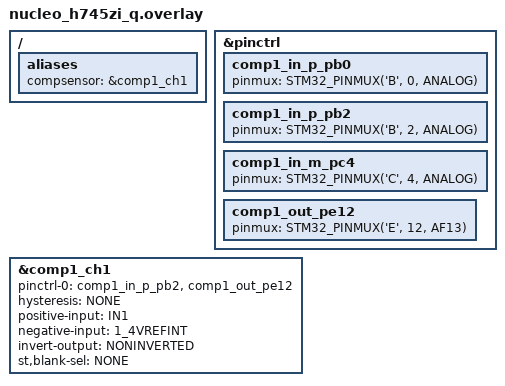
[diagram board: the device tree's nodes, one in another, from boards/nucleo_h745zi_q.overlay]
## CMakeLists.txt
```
# SPDX-License-Identifier: Apache-2.0
# Copyright (c) 2025 Alexander Kozhinov <ak.alexander.kozhinov@gmail.com>

cmake_minimum_required(VERSION 3.20.0)
find_package(Zephyr REQUIRED HINTS $ENV{ZEPHYR_BASE})
project(comparator)

target_sources(app PRIVATE src/main.c)
```

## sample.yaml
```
sample:
  name: Comparator API sample
tests:
  sample.drivers.comparator:
    tags:
      - comparator
    depends_on: comparator
    platform_allow:
      - nucleo_h745zi_q/stm32h745xx/m7
    harness: console
    timeout: 10
    harness_config:
      type: one_line
      regex:
        - "comparator@.* output: \\d+"
```

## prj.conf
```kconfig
CONFIG_GPIO=y
CONFIG_COMPARATOR=y

CONFIG_HW_STACK_PROTECTION=y

CONFIG_LOG=y
CONFIG_COMPARATOR_LOG_LEVEL_DBG=y
```

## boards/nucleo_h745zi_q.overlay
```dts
/*
 * SPDX-License-Identifier: Apache-2.0
 * Copyright (c) 2025 Alexander Kozhinov <ak.alexander.kozhinov@gmail.com>
 */

/ {
	aliases {
		compsensor = &comp1_ch1;
	};
};

&pinctrl {
	/omit-if-no-ref/ comp1_in_p_pb0: comp1_in_p_pb0 {
		pinmux = <STM32_PINMUX('B', 0, ANALOG)>;
	};

	/omit-if-no-ref/ comp1_in_p_pb2: comp1_in_p_pb2 {
		pinmux = <STM32_PINMUX('B', 2, ANALOG)>;
	};

	/omit-if-no-ref/ comp1_in_m_pc4: comp1_in_m_pc4 {
		pinmux = <STM32_PINMUX('C', 4, ANALOG)>;
	};

	/omit-if-no-ref/ comp1_out_pe12: comp1_out_pe12 {
		pinmux = <STM32_PINMUX('E', 12, AF13)>;
	};
};

/*
 * On nucleo-h745zi-q board the led0 is connected to PB0 (D33 on CN10).
 * led0 will be toggled every 3rd run of the main cycle as an GPIO thus
 * led0 will get on and off.
 * Thus the pin PB0 may be connected to PB2 (D27 on CN10) to trigger COMP1
 * state change.
 */
&comp1_ch1 {
	status = "okay";
	pinctrl-0 = <&comp1_in_p_pb2 &comp1_out_pe12>;
	pinctrl-names = "default";
	hysteresis = "NONE";
	positive-input = "IN1";
	negative-input = "1_4VREFINT";
	invert-output = "NONINVERTED";
	st,blank-sel = "NONE";
};
```

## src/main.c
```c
/*
 * Copyright (c) 2025 Alexander Kozhinov <ak.alexander.kozhinov@gmail.com>
 * SPDX-License-Identifier: Apache-2.0
 */

#include <zephyr/kernel.h>
#include <zephyr/device.h>
#include <zephyr/devicetree.h>
#include <zephyr/drivers/gpio.h>
#include <zephyr/drivers/comparator.h>

#define SLEEP_TIME_MS		500

/* COMP node from device tree */
#define COMP_SENSOR_NODE DT_ALIAS(compsensor)
#if DT_NODE_HAS_STATUS(COMP_SENSOR_NODE, okay)
static const struct device *comp_sens_dev = DEVICE_DT_GET(COMP_SENSOR_NODE);
#else
#error "COMP1 node is disabled"
#endif

#define LED0_NODE DT_ALIAS(led0)
static const struct gpio_dt_spec led = GPIO_DT_SPEC_GET(LED0_NODE, gpios);

void comp_trigger_cb(const struct device *dev, void *user_data)
{
	const int ret = comparator_get_output(dev);

	printf("- %s: %s output: %d\n", __func__, dev->name, ret);
}

int main(void)
{
	int ret = 0;
	size_t cnt = 0;

	if (!gpio_is_ready_dt(&led)) {
		return ret;
	}

	ret = gpio_pin_configure_dt(&led, GPIO_OUTPUT_ACTIVE);
	if (ret < 0) {
		return ret;
	}

	ret = device_is_ready(comp_sens_dev);
	if (!ret) {
		printk("Device not ready: comp1 (err: %d)\n", ret);
		return ret;
	}

	ret = comparator_set_trigger_callback(comp_sens_dev, &comp_trigger_cb, NULL);
	if (ret != 0) {
		printk("Failed to set trigger callback: %s (err: %d)\n",
				comp_sens_dev->name, ret);
		return ret;
	}

	ret = comparator_set_trigger(comp_sens_dev, COMPARATOR_TRIGGER_BOTH_EDGES);
	if (ret != 0) {
		printk("Failed to set trigger: %s (err: %d)\n",
				comp_sens_dev->name, ret);
		return ret;
	}

#ifndef CONFIG_COVERAGE
	while (1) {
#else
	for (int k = 0; k < 10; k++) {
#endif
		k_msleep(SLEEP_TIME_MS);

		if (cnt % 3 == 0) {
			ret = gpio_pin_toggle_dt(&led);
			if (ret < 0) {
				printk("can't toggle led: exit (err: %d)\n", ret);
				return ret;
			}
		}

		ret = comparator_get_output(comp_sens_dev);
		printf("- %s output: %d\n", comp_sens_dev->name, ret);

		cnt++;
	}

	return 0;
}
```
